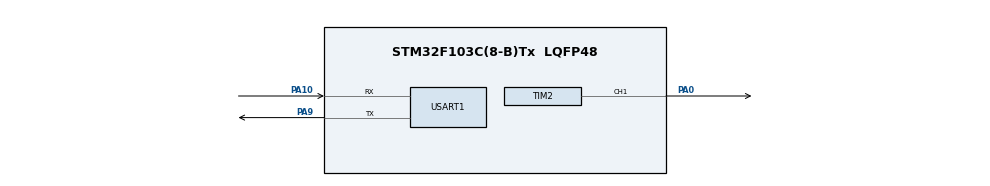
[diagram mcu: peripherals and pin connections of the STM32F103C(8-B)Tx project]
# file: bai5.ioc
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Mcu.Family=STM32F1
Mcu.Name=STM32F103C(8-B)Tx
Mcu.Package=LQFP48
NVIC.PriorityGroup=NVIC_PRIORITYGROUP_4
NVIC.USART1_IRQn=true\:0\:0\:false\:false\:true\:true\:true\:true
PA0-WKUP.Signal=S_TIM2_CH1_ETR
PA10.Mode=Asynchronous
PA10.Signal=USART1_RX
PA13.Mode=Serial_Wire
PA13.Signal=SYS_JTMS-SWDIO
PA14.Mode=Serial_Wire
PA14.Signal=SYS_JTCK-SWCLK
PA9.Mode=Asynchronous
PA9.Signal=USART1_TX
ProjectManager.HeapSize=0x200
ProjectManager.StackSize=0x400
ProjectManager.TargetToolchain=Makefile
RCC.APB1Freq_Value=8000000
RCC.APB2Freq_Value=8000000
SH.S_TIM2_CH1_ETR.0=TIM2_CH1,PWM Generation1 CH1
TIM2.Channel-PWM\ Generation1\ CH1=TIM_CHANNEL_1
USART1.VirtualMode=VM_ASYNC
board=custom

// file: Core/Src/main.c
/* USER CODE BEGIN Header */
/**
  ******************************************************************************
  * @file           : main.c
  * @brief          : Main program body
  ******************************************************************************
  * @attention
  *
  * Copyright (c) 2026 STMicroelectronics.
  * All rights reserved.
  *
  * This software is licensed under terms that can be found in the LICENSE file
  * in the root directory of this software component.
  * If no LICENSE file comes with this software, it is provided AS-IS.
  *
  ******************************************************************************
  */
/* USER CODE END Header */
#include "main.h"

/* USER CODE BEGIN Includes */
#include <stdio.h>
#include <string.h>

/* USER CODE END Includes */

TIM_HandleTypeDef htim2;

UART_HandleTypeDef huart1;

/* USER CODE BEGIN PV */
static uint8_t uart_rx_byte;
static char command_buffer[32];
static uint8_t command_length;
static uint16_t pwm_percent = 100;
static uint8_t led_enabled;

/* USER CODE END PV */

void SystemClock_Config(void);
static void MX_GPIO_Init(void);
static void MX_TIM2_Init(void);
static void MX_USART1_UART_Init(void);

/* USER CODE BEGIN 0 */
static void Uart_Send(const char *message)
{
  HAL_UART_Transmit(&huart1, (uint8_t *)message, strlen(message), HAL_MAX_DELAY);
}

static void Apply_Pwm(void)
{
  uint32_t pulse = ((uint32_t)pwm_percent * (__HAL_TIM_GET_AUTORELOAD(&htim2) + 1U)) / 100U;

  if (pulse > __HAL_TIM_GET_AUTORELOAD(&htim2))
  {
    pulse = __HAL_TIM_GET_AUTORELOAD(&htim2);
  }
  __HAL_TIM_SET_COMPARE(&htim2, TIM_CHANNEL_1, led_enabled ? pulse : 0U);
}

static void Process_Command(void)
{
  char response[48];
  unsigned int percent;

  command_buffer[command_length] = '\0';

  if (strcmp(command_buffer, "ON") == 0)
  {
    led_enabled = 1U;
    Apply_Pwm();
    Uart_Send("LED ON\r\n");
  }
  else if (strcmp(command_buffer, "OFF") == 0)
  {
    led_enabled = 0U;
    Apply_Pwm();
    Uart_Send("LED OFF\r\n");
  }
  else if (sscanf(command_buffer, "PWM:%u", &percent) == 1 && percent <= 100U)
  {
    pwm_percent = (uint16_t)percent;
    Apply_Pwm();
    Uart_Send("PWM OK\r\n");
  }
  else if (strcmp(command_buffer, "Status") == 0)
  {
    snprintf(response, sizeof(response), "LED:%s PWM:%u%%\r\n",
             led_enabled ? "ON" : "OFF", pwm_percent);
    Uart_Send(response);
  }
  else
  {
    Uart_Send("ERR\r\n");
  }

  command_length = 0U;
}

/* USER CODE END 0 */

int main(void)
{

  /* MCU Configuration--------------------------------------------------------*/

  /* Reset of all peripherals, Initializes the Flash interface and the Systick. */
  HAL_Init();

  /* Configure the system clock */
  SystemClock_Config();

  /* Initialize all configured peripherals */
  MX_GPIO_Init();
  MX_TIM2_Init();
  MX_USART1_UART_Init();
  /* USER CODE BEGIN 2 */
  HAL_TIM_PWM_Start(&htim2, TIM_CHANNEL_1);
  Apply_Pwm();
  HAL_UART_Receive_IT(&huart1, &uart_rx_byte, 1U);
  Uart_Send("Ready\r\n");

  /* USER CODE END 2 */

  /* Infinite loop */
  while (1)
  {

  }
}

void SystemClock_Config(void)
{
  RCC_OscInitTypeDef RCC_OscInitStruct = {0};
  RCC_ClkInitTypeDef RCC_ClkInitStruct = {0};

  /** Initializes the RCC Oscillators according to the specified parameters
  * in the RCC_OscInitTypeDef structure.
  */
  RCC_OscInitStruct.OscillatorType = RCC_OSCILLATORTYPE_HSI;
  RCC_OscInitStruct.HSIState = RCC_HSI_ON;
  RCC_OscInitStruct.HSICalibrationValue = RCC_HSICALIBRATION_DEFAULT;
  RCC_OscInitStruct.PLL.PLLState = RCC_PLL_NONE;
  if (HAL_RCC_OscConfig(&RCC_OscInitStruct) != HAL_OK)
  {
    Error_Handler();
  }

  /** Initializes the CPU, AHB and APB buses clocks
  */
  RCC_ClkInitStruct.ClockType = RCC_CLOCKTYPE_HCLK|RCC_CLOCKTYPE_SYSCLK
                              |RCC_CLOCKTYPE_PCLK1|RCC_CLOCKTYPE_PCLK2;
  RCC_ClkInitStruct.SYSCLKSource = RCC_SYSCLKSOURCE_HSI;
  RCC_ClkInitStruct.AHBCLKDivider = RCC_SYSCLK_DIV1;
  RCC_ClkInitStruct.APB1CLKDivider = RCC_HCLK_DIV1;
  RCC_ClkInitStruct.APB2CLKDivider = RCC_HCLK_DIV1;

  if (HAL_RCC_ClockConfig(&RCC_ClkInitStruct, FLASH_LATENCY_0) != HAL_OK)
  {
    Error_Handler();
  }
}

static void MX_TIM2_Init(void)
{

  TIM_MasterConfigTypeDef sMasterConfig = {0};
  TIM_OC_InitTypeDef sConfigOC = {0};

  htim2.Instance = TIM2;
  htim2.Init.Prescaler = 0;
  htim2.Init.CounterMode = TIM_COUNTERMODE_UP;
  htim2.Init.Period = 65535;
  htim2.Init.ClockDivision = TIM_CLOCKDIVISION_DIV1;
  htim2.Init.AutoReloadPreload = TIM_AUTORELOAD_PRELOAD_DISABLE;
  if (HAL_TIM_PWM_Init(&htim2) != HAL_OK)
  {
    Error_Handler();
  }
  sMasterConfig.MasterOutputTrigger = TIM_TRGO_RESET;
  sMasterConfig.MasterSlaveMode = TIM_MASTERSLAVEMODE_DISABLE;
  if (HAL_TIMEx_MasterConfigSynchronization(&htim2, &sMasterConfig) != HAL_OK)
  {
    Error_Handler();
  }
  sConfigOC.OCMode = TIM_OCMODE_PWM1;
  sConfigOC.Pulse = 0;
  sConfigOC.OCPolarity = TIM_OCPOLARITY_HIGH;
  sConfigOC.OCFastMode = TIM_OCFAST_DISABLE;
  if (HAL_TIM_PWM_ConfigChannel(&htim2, &sConfigOC, TIM_CHANNEL_1) != HAL_OK)
  {
    Error_Handler();
  }
  HAL_TIM_MspPostInit(&htim2);

}

static void MX_USART1_UART_Init(void)
{

  huart1.Instance = USART1;
  huart1.Init.BaudRate = 115200;
  huart1.Init.WordLength = UART_WORDLENGTH_8B;
  huart1.Init.StopBits = UART_STOPBITS_1;
  huart1.Init.Parity = UART_PARITY_NONE;
  huart1.Init.Mode = UART_MODE_TX_RX;
  huart1.Init.HwFlowCtl = UART_HWCONTROL_NONE;
  huart1.Init.OverSampling = UART_OVERSAMPLING_16;
  if (HAL_UART_Init(&huart1) != HAL_OK)
  {
    Error_Handler();
  }

}

static void MX_GPIO_Init(void)
{

  /* GPIO Ports Clock Enable */
  __HAL_RCC_GPIOA_CLK_ENABLE();

}

/* USER CODE BEGIN 4 */
void HAL_UART_RxCpltCallback(UART_HandleTypeDef *huart)
{
  if (huart->Instance == USART1)
  {
    if (uart_rx_byte == '!')
    {
      Process_Command();
    }
    else if (uart_rx_byte != '\r' && uart_rx_byte != '\n' &&
             command_length < sizeof(command_buffer) - 1U)
    {
      command_buffer[command_length++] = (char)uart_rx_byte;
    }

    HAL_UART_Receive_IT(&huart1, &uart_rx_byte, 1U);
  }
}

/* USER CODE END 4 */

void Error_Handler(void)
{
  __disable_irq();
  while (1)
  {
  }
}
